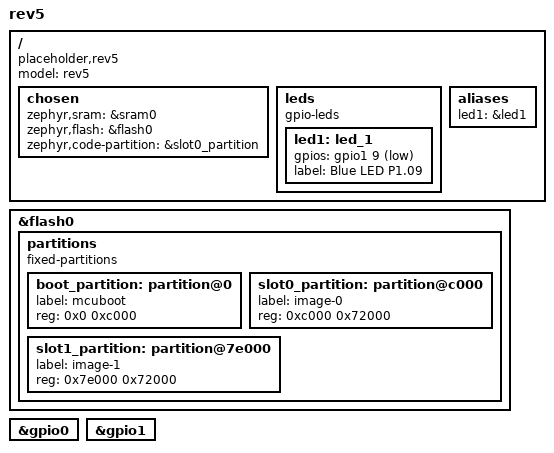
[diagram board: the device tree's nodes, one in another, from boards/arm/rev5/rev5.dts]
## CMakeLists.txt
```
# SPDX-License-Identifier: Apache-2.0

cmake_minimum_required(VERSION 3.20.0)
# set(ZEPHYR_MODULES /home/k/proj/tab_firmware/tab_firmware/liblc3)
find_package(Zephyr REQUIRED HINTS $ENV{ZEPHYR_BASE})
project(nrf_tab2)

target_sources(app PRIVATE src/main.c)

# target_include_directories(app PRIVATE
#   src/lc3lib
# )
#   src/lc3lib

# add_subdirectory(src/impl)
# add_subdirectory(src/lc3lib)

# seemingly unnecessary even though present in all examples?
# zephyr_library_include_directories(src/impl)
```

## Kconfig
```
# Copyright (c) 2024 Nordic Semiconductor ASA
# SPDX-License-Identifier: Apache-2.0


mainmenu "Customized Menu Name"
source "Kconfig.zephyr"

menu "Application Options"

endmenu
```

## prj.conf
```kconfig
# CONFIG_BT_SMP=y
CONFIG_GPIO=y

## Ensure an MCUboot-compatible binary is generated.
CONFIG_BOOTLOADER_MCUBOOT=y

CONFIG_BT=y
CONFIG_BT_DEVICE_NAME="Device1235"
CONFIG_BT_PERIPHERAL=y

# Allow for large Bluetooth data packets.
CONFIG_BT_L2CAP_TX_MTU=498
CONFIG_BT_BUF_ACL_RX_SIZE=502
CONFIG_BT_BUF_ACL_TX_SIZE=502
CONFIG_BT_CTLR_DATA_LENGTH_MAX=251

# Enable the Bluetooth mcumgr transport (unauthenticated).
CONFIG_MCUMGR_TRANSPORT_BT=y
CONFIG_MCUMGR_TRANSPORT_BT_AUTHEN=n
CONFIG_MCUMGR_TRANSPORT_BT_CONN_PARAM_CONTROL=y

CONFIG_MCUMGR_TRANSPORT_BT_REASSEMBLY=y
CONFIG_MCUMGR_TRANSPORT_NETBUF_SIZE=2475

CONFIG_MCUMGR_GRP_OS=y
# enable MCUMGR Parameters retrieval command
CONFIG_MCUMGR_GRP_OS_MCUMGR_PARAMS=y
CONFIG_MCUMGR_TRANSPORT_WORKQUEUE_STACK_SIZE=4608
CONFIG_NCS_SAMPLE_MCUMGR_BT_OTA_DFU=y

CONFIG_NET_BUF=y
CONFIG_ZCBOR=y
#CONFIG_CRC=y
CONFIG_MCUMGR=y
CONFIG_STREAM_FLASH=y
CONFIG_FLASH_MAP=y
CONFIG_FLASH=y

# Some command handlers require a large stack.
CONFIG_SYSTEM_WORKQUEUE_STACK_SIZE=2304
CONFIG_MAIN_STACK_SIZE=2048
# CONFIG_MAIN_STACK_SIZE=4096

# never did anything?? idk i swear it used to...
# CONFIG_BT_HCI_CORE_LOG_LEVEL_WRN=y
# CONFIG_BT_HCI_DRIVER_LOG_LEVEL_WRN=y

# enable STDOUT as early as possible for debugging accuracy
CONFIG_EARLY_CONSOLE=y
CONFIG_LOG_MODE_IMMEDIATE=y

CONFIG_PINCTRL=y
CONFIG_CLOCK_CONTROL=y
CONFIG_CLOCK_CONTROL_NRF_K32SRC_RC=y
CONFIG_DEBUG_OPTIMIZATIONS=y
CONFIG_LOG=y

## Enable the storage erase command.
#CONFIG_MCUMGR_GRP_ZBASIC=y
#CONFIG_MCUMGR_GRP_ZBASIC_STORAGE_ERASE=y
#
## Disable shell commands that are not needed
#CONFIG_CLOCK_CONTROL_NRF_SHELL=n
#CONFIG_DEVICE_SHELL=n
#CONFIG_DEVMEM_SHELL=n
#CONFIG_FLASH_SHELL=n
#
## Required by the `taskstat` command.
#CONFIG_THREAD_MONITOR=y
#
## Support for taskstat command
#CONFIG_MCUMGR_GRP_OS_TASKSTAT=y
#
## Enable statistics and statistic names.
#CONFIG_STATS=y
#CONFIG_STATS_NAMES=y
#
## Enable most core commands.
#CONFIG_FLASH=y
#CONFIG_IMG_MANAGER=y
#CONFIG_MCUMGR_GRP_IMG=y
#CONFIG_MCUMGR_GRP_OS=y
#CONFIG_MCUMGR_GRP_STAT=y
#
```

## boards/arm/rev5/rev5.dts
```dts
// Copyright (c) 2024 Nordic Semiconductor ASA
// SPDX-License-Identifier: Apache-2.0

/dts-v1/;
#include <nordic/nrf52840_qfaa.dtsi>

/ {
    model = "rev5";
    compatible = "placeholder,rev5";

    chosen {
    	zephyr,sram = &sram0;
    	zephyr,flash = &flash0;
    	zephyr,code-partition = &slot0_partition;
    };
    leds {
        compatible = "gpio-leds";
        led1: led_1 {
            gpios = <&gpio1 9 (GPIO_ACTIVE_LOW)>;
            label = "Blue LED P1.09";
        };
    };

    aliases {
        led1 = &led1;
    };
};

&flash0 {
	partitions {
		compatible = "fixed-partitions";
		#address-cells = <1>;
		#size-cells = <1>;

		boot_partition: partition@0 {
			label = "mcuboot";
			reg = <0x0 0xc000>;
		};
		slot0_partition: partition@c000 {
			label = "image-0";
			reg = <0xc000 0x72000>;
		};
		slot1_partition: partition@7e000 {
			label = "image-1";
			reg = <0x7e000 0x72000>;
		};
		// scratch_partition: partition@f0000 {
		// 	label = "image-scratch";
		// 	reg = <0xf0000 0xa000>;
		// };
		// storage_partition: partition@fa000 {
		// 	label = "storage";
		// 	reg = <0xfa000 0x6000>;
		// };
	};
};

&gpio0 {
    status = "okay";
};
&gpio1 {
    status = "okay";
};
```

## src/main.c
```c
#include <zephyr/kernel.h>
#include <zephyr/logging/log.h>
#include <zephyr/drivers/gpio.h>

LOG_MODULE_REGISTER(main, 4);

static struct gpio_dt_spec ledBlue = GPIO_DT_SPEC_GET(DT_ALIAS(led1), gpios);

int main(void)
{
  gpio_pin_configure_dt(&ledBlue, GPIO_OUTPUT_ACTIVE); // returns int (leaving that unhandled unless this ever fails)
	bool led_on = 1;
	for(;;){
			led_on = !led_on;
			gpio_pin_set_dt(&ledBlue, led_on);
			LOG_ERR("blink");
			k_msleep(500);
	}
	// TODO: put actual smp svr code here
}
```
